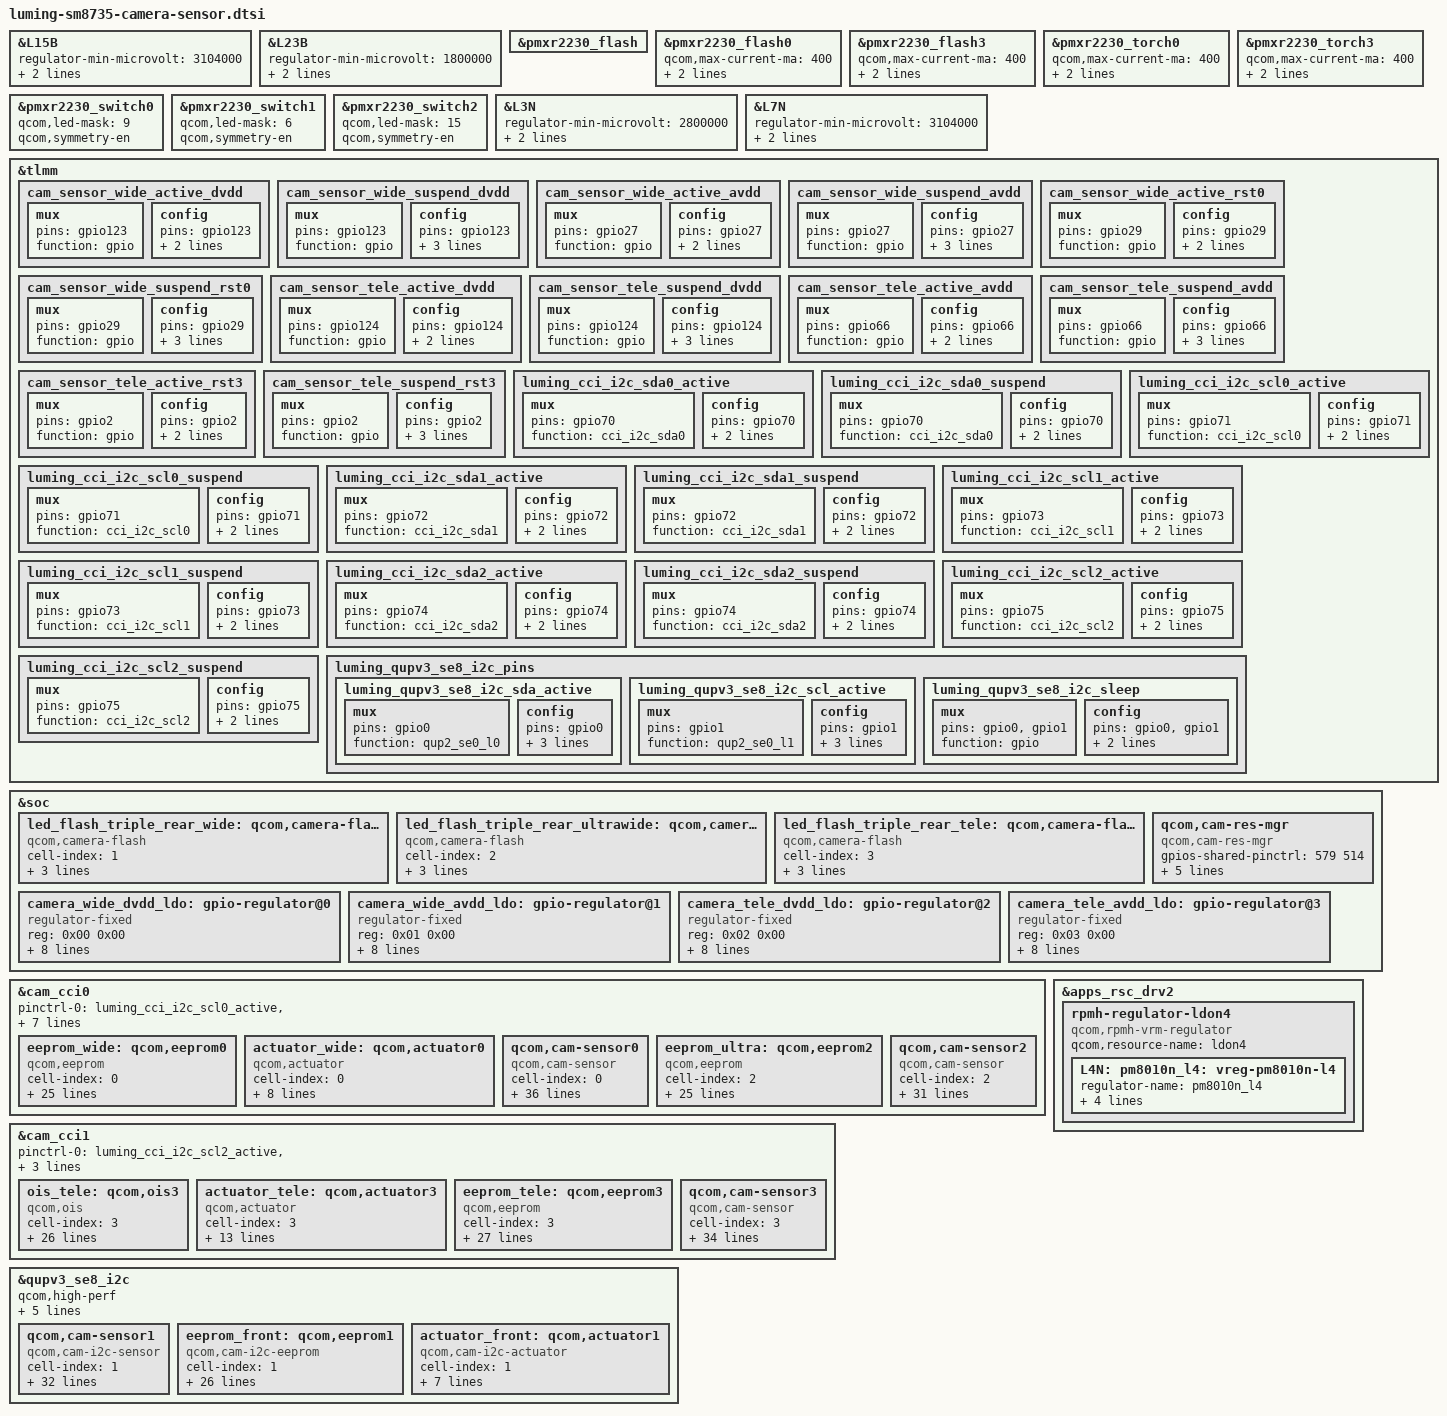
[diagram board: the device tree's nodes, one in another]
#include <dt-bindings/msm-camera.h>
&L15B {
	regulator-min-microvolt = <3104000>;
	regulator-max-microvolt = <3104000>;
	qcom,init-voltage = <3104000>;
};

&L23B {
	regulator-min-microvolt = <1800000>;
	regulator-max-microvolt = <1800000>;
	qcom,init-voltage = <1800000>;
};

&pmxr2230_flash {
	status = "ok";
};

&pmxr2230_flash0 {
	qcom,max-current-ma = <400>;
	qcom,duration-ms = <300>;
	xiaomi,max-duration-ms = <300>;
};

&pmxr2230_flash3 {
	qcom,max-current-ma = <400>;
	qcom,duration-ms = <300>;
	xiaomi,max-duration-ms = <300>;
};

&pmxr2230_torch0 {
	qcom,max-current-ma = <400>;
	xiaomi,currents-with-time = <400 150>;
	xiaomi,time-for-currents = <5000 0xFFFFFFFF>;
};

&pmxr2230_torch3 {
	qcom,max-current-ma = <400>;
	xiaomi,currents-with-time = <400 150>;
	xiaomi,time-for-currents = <5000 0xFFFFFFFF>;
};

&pmxr2230_switch0 {
	qcom,led-mask = <9>; /* Channels 1 & 4 */
	qcom,symmetry-en;
};

&pmxr2230_switch1 {
	qcom,led-mask = <6>; /* Channels 2 & 3 */
	qcom,symmetry-en;
};

&pmxr2230_switch2 {
	qcom,led-mask = <15>; /* All Channels */
	qcom,symmetry-en;
};


&L3N {
	regulator-min-microvolt = <2800000>;
	regulator-max-microvolt = <2800000>;
	qcom,init-voltage = <2800000>;
};

&L7N {
	regulator-min-microvolt = <3104000>;
	regulator-max-microvolt = <3104000>;
	qcom,init-voltage = <3104000>;
};

&tlmm {
	//WIDE DVDD
	cam_sensor_wide_active_dvdd: cam_sensor_wide_active_dvdd {
		mux {
			pins = "gpio123";
			function = "gpio";
		};
		config {
			pins = "gpio123";
			bias-disable; /* No PULL */
			drive-strength = <2>; /* 2 MA */
		};
	};
	cam_sensor_wide_suspend_dvdd: cam_sensor_wide_suspend_dvdd {
		mux {
			pins = "gpio123";
			function = "gpio";
		};
		config {
			pins = "gpio123";
			bias-pull-down; /* PULL DOWN */
			drive-strength = <2>; /* 2 MA */
			output-low;
		};
	};

	//WIDE AVDD
	cam_sensor_wide_active_avdd: cam_sensor_wide_active_avdd {
		mux {
			pins = "gpio27";
			function = "gpio";
		};
		config {
			pins = "gpio27";
			bias-disable; /* No PULL */
			drive-strength = <2>; /* 2 MA */
		};
	};
	cam_sensor_wide_suspend_avdd: cam_sensor_wide_suspend_avdd {
		mux {
			pins = "gpio27";
			function = "gpio";
		};
		config {
			pins = "gpio27";
			bias-pull-down; /* PULL DOWN */
			drive-strength = <2>; /* 2 MA */
			output-low;
		};
	};
	//WIDE RST
	cam_sensor_wide_active_rst0: cam_sensor_wide_active_rst0 {
		mux {
			pins = "gpio29";
			function = "gpio";
		};

		config {
			pins = "gpio29";
			bias-disable; /* No PULL */
			drive-strength = <2>; /* 2 MA */
		};
	};

	cam_sensor_wide_suspend_rst0: cam_sensor_wide_suspend_rst0 {
		mux {
			pins = "gpio29";
			function = "gpio";
		};

		config {
			pins = "gpio29";
			bias-pull-down; /* PULL DOWN */
			drive-strength = <2>; /* 2 MA */
			output-low;
		};
	};

	// Tele DVDD
	cam_sensor_tele_active_dvdd: cam_sensor_tele_active_dvdd {
		mux {
			pins = "gpio124";
			function = "gpio";
		};
		config {
			pins = "gpio124";
			bias-disable; /* No PULL */
			drive-strength = <2>; /* 2 MA */
		};
	};
	cam_sensor_tele_suspend_dvdd: cam_sensor_tele_suspend_dvdd {
		mux {
			pins = "gpio124";
			function = "gpio";
		};
		config {
			pins = "gpio124";
			bias-pull-down; /* PULL DOWN */
			drive-strength = <2>; /* 2 MA */
			output-low;
		};
	};

	//TELE AVDD
	cam_sensor_tele_active_avdd: cam_sensor_tele_active_avdd {
		mux {
			pins = "gpio66";
			function = "gpio";
		};
		config {
			pins = "gpio66";
			bias-disable; /* No PULL */
			drive-strength = <2>; /* 2 MA */
		};
	};
	cam_sensor_tele_suspend_avdd: cam_sensor_tele_suspend_avdd {
		mux {
			pins = "gpio66";
			function = "gpio";
		};
		config {
			pins = "gpio66";
			bias-pull-down; /* PULL DOWN */
			drive-strength = <2>; /* 2 MA */
			output-low;
		};
	};

	// Tele RST
	cam_sensor_tele_active_rst3: cam_sensor_tele_active_rst3 {
		mux {
			pins = "gpio2";
			function = "gpio";
		};

		config {
			pins = "gpio2";
			bias-disable; /* No PULL */
			drive-strength = <2>; /* 2 MA */
		};
	};

	cam_sensor_tele_suspend_rst3: cam_sensor_tele_suspend_rst3 {
		mux {
			pins = "gpio2";
			function = "gpio";
		};

		config {
			pins = "gpio2";
			bias-pull-down; /* PULL DOWN */
			drive-strength = <2>; /* 2 MA */
			output-low;
		};
	};

	// wide cci
	luming_cci_i2c_sda0_active: luming_cci_i2c_sda0_active {
		mux {
			pins = "gpio70";
			function = "cci_i2c_sda0";
		};

		config {
			pins = "gpio70";
			bias-disable; /* NO PULL */
			drive-strength = <2>; /* 2 MA */
		};
	};
	luming_cci_i2c_sda0_suspend: luming_cci_i2c_sda0_suspend {
		mux {
			pins = "gpio70";
			function = "cci_i2c_sda0";
		};

		config {
			pins = "gpio70";
			bias-disable; /* NO PULL */
			drive-strength = <2>; /* 2 MA */
		};
	};

	luming_cci_i2c_scl0_active: luming_cci_i2c_scl0_active {
		mux {
			pins = "gpio71";
			function = "cci_i2c_scl0";
		};

		config {
			pins = "gpio71";
			bias-disable; /* NO PULL */
			drive-strength = <2>; /* 2 MA */
		};
	};
	luming_cci_i2c_scl0_suspend: luming_cci_i2c_scl0_suspend {
		mux {
			pins = "gpio71";
			function = "cci_i2c_scl0";
		};
		config {
			pins = "gpio71";
			bias-disable; /* NO PULL */
			drive-strength = <2>; /* 2 MA */
		};
	};

	// ultra cci
	luming_cci_i2c_sda1_active: luming_cci_i2c_sda1_active {
		mux {
			pins = "gpio72";
			function = "cci_i2c_sda1";
		};

		config {
			pins = "gpio72";
			bias-disable; /* NO PULL */
			drive-strength = <2>; /* 2 MA */
		};
	};

	luming_cci_i2c_sda1_suspend: luming_cci_i2c_sda1_suspend {
		mux {
			pins = "gpio72";
			function = "cci_i2c_sda1";
		};
		config {
			pins = "gpio72";
			bias-disable; /* NO PULL */
			drive-strength = <2>; /* 2 MA */
		};
	};

	luming_cci_i2c_scl1_active: luming_cci_i2c_scl1_active {
		mux {
			pins = "gpio73";
			function = "cci_i2c_scl1";
		};

		config {
			pins = "gpio73";
			bias-disable; /* NO PULL */
			drive-strength = <2>; /* 2 MA */
		};
	};
	luming_cci_i2c_scl1_suspend: luming_cci_i2c_scl1_suspend {
		mux {
			pins = "gpio73";
			function = "cci_i2c_scl1";
		};
		config {
			pins = "gpio73";
			bias-disable; /* NO PULL */
			drive-strength = <2>; /* 2 MA */
		};
	};

	// tele cci
	luming_cci_i2c_sda2_active: luming_cci_i2c_sda2_active {
		mux {
			pins = "gpio74";
			function = "cci_i2c_sda2";
		};
		config {
			pins = "gpio74";
			bias-disable; /* NO PULL */
			drive-strength = <2>; /* 2 MA */
		};
	};
	luming_cci_i2c_sda2_suspend: luming_cci_i2c_sda2_suspend {
		mux {
			pins = "gpio74";
			function = "cci_i2c_sda2";
		};
		config {
			pins = "gpio74";
			bias-disable; /* NO PULL */
			drive-strength = <2>; /* 2 MA */
		};
	};


	luming_cci_i2c_scl2_active: luming_cci_i2c_scl2_active {
		mux {
			pins = "gpio75";
			function = "cci_i2c_scl2";
		};
		config {
			pins = "gpio75";
			bias-disable; /* NO PULL */
			drive-strength = <2>; /* 2 MA */
		};
	};
	luming_cci_i2c_scl2_suspend: luming_cci_i2c_scl2_suspend {
		mux {
			pins = "gpio75";
			function = "cci_i2c_scl2";
		};
		config {
			pins = "gpio75";
			bias-disable; /* NO PULL */
			drive-strength = <2>; /* 2 MA */
		};
	};
	luming_qupv3_se8_i2c_pins: luming_qupv3_se8_i2c_pins {
		luming_qupv3_se8_i2c_sda_active: luming_qupv3_se8_i2c_sda_active {
			mux {
				pins = "gpio0";
				function = "qup2_se0_l0";
			};

			config {
				pins = "gpio0";
				drive-strength = <2>;
				bias-disable;
				qcom,apps;
			};
		};

		luming_qupv3_se8_i2c_scl_active: luming_qupv3_se8_i2c_scl_active {
			mux {
				pins = "gpio1";
				function = "qup2_se0_l1";
			};

			config {
				pins = "gpio1";
				drive-strength = <2>;
				bias-disable;
				qcom,apps;
			};
		};
		luming_qupv3_se8_i2c_sleep: luming_qupv3_se8_i2c_sleep {
			mux {
				pins = "gpio0", "gpio1";
				function = "gpio";
			};

			config {
				pins = "gpio0", "gpio1";
				drive-strength = <2>;
				qcom,remote;
			};
		};
	};
};

&soc {
	led_flash_triple_rear_wide: qcom,camera-flash1 {
		cell-index = <1>;
		compatible = "qcom,camera-flash";
		flash-source = <&pmxr2230_flash0>;
		torch-source = <&pmxr2230_torch0>;
		switch-source = <&pmxr2230_switch0>;
		status = "ok";
	};

	led_flash_triple_rear_ultrawide: qcom,camera-flash2 {
		cell-index = <2>;
		compatible = "qcom,camera-flash";
		flash-source = <&pmxr2230_flash0>;
		torch-source = <&pmxr2230_torch0>;
		switch-source = <&pmxr2230_switch0>;
		status = "ok";
	};

	led_flash_triple_rear_tele: qcom,camera-flash3 {
		cell-index = <3>;
		compatible = "qcom,camera-flash";
		flash-source = <&pmxr2230_flash0>;
		torch-source = <&pmxr2230_torch0>;
		switch-source = <&pmxr2230_switch0>;
		status = "ok";
	};

	qcom,cam-res-mgr {
		compatible = "qcom,cam-res-mgr";
		gpios-shared-pinctrl = <579 514>;
		shared-pctrl-gpio-names = "cam_tele", "cam_tele";
		pinctrl-names = "cam_tele_active", "cam_tele_suspend";
		pinctrl-0 = <&cam_sensor_mclk3_active
					&cam_sensor_tele_active_rst3>;
		pinctrl-1 = <&cam_sensor_mclk3_suspend
					&cam_sensor_tele_suspend_rst3>;
		status = "ok";
	};

	camera_wide_dvdd_ldo: gpio-regulator@0 {
		compatible = "regulator-fixed";
		reg = <0x00 0x00>;
		regulator-name = "camera_wide_dvdd_ldo";
		regulator-min-microvolt = <1104000>;
		regulator-max-microvolt = <1104000>;
		regulator-enable-ramp-delay = <100>;
		enable-active-high;
		gpio = <&tlmm 123 0>;
		pinctrl-names = "wide_dvdd_active", "wide_dvdd_suspend";
		pinctrl-0 = <&cam_sensor_wide_active_dvdd
					 &cam_sensor_wide_suspend_dvdd>;
	};

	camera_wide_avdd_ldo: gpio-regulator@1 {
		compatible = "regulator-fixed";
		reg = <0x01 0x00>;
		regulator-name = "camera_wide_avdd_ldo";
		regulator-min-microvolt = <2800000>;
		regulator-max-microvolt = <2800000>;
		regulator-enable-ramp-delay = <100>;
		enable-active-high;
		gpio = <&tlmm 27 0>;
		pinctrl-names = "wide_avdd_active", "wide_avdd_suspend";
		pinctrl-0 = <&cam_sensor_wide_active_avdd
					 &cam_sensor_wide_suspend_avdd>;
	};

	camera_tele_dvdd_ldo: gpio-regulator@2 {
		compatible = "regulator-fixed";
		reg = <0x02 0x00>;
		regulator-name = "camera_tele_dvdd_ldo";
		regulator-min-microvolt = <1000000>;
		regulator-max-microvolt = <1000000>;
		regulator-enable-ramp-delay = <100>;
		enable-active-high;
		gpio = <&tlmm 124 0>;
		pinctrl-names = "tele_dvdd_active", "tele_dvdd_suspend";
		pinctrl-0 = <&cam_sensor_tele_active_dvdd
					 &cam_sensor_tele_suspend_dvdd>;
	};

	camera_tele_avdd_ldo: gpio-regulator@3 {
		compatible = "regulator-fixed";
		reg = <0x03 0x00>;
		regulator-name = "camera_tele_avdd_ldo";
		regulator-min-microvolt = <2200000>;
		regulator-max-microvolt = <2200000>;
		regulator-enable-ramp-delay = <100>;
		enable-active-high;
		gpio = <&tlmm 66 0>;
		pinctrl-names = "tele_avdd_active", "tele_avdd_suspend";
		pinctrl-0 = <&cam_sensor_tele_active_avdd
					 &cam_sensor_tele_suspend_avdd>;
	};
};

&cam_cci0 {
	pinctrl-0 = <&luming_cci_i2c_scl0_active &luming_cci_i2c_sda0_active>;
	pinctrl-1 = <&luming_cci_i2c_scl0_suspend &luming_cci_i2c_sda0_suspend>;
	pinctrl-2 = <&luming_cci_i2c_scl1_active &luming_cci_i2c_sda1_active>;
	pinctrl-3 = <&luming_cci_i2c_scl1_suspend &luming_cci_i2c_sda1_suspend>;
	// wide eeprom
	eeprom_wide: qcom,eeprom0 {
		cell-index = <0>;
		compatible = "qcom,eeprom";
		cam_vio-supply = <&L23B>;
		cam_vdig-supply = <&camera_wide_dvdd_ldo>;
		cam_clk-supply = <&cam_cc_titan_top_gdsc>;
		cam_vana-supply = <&camera_wide_avdd_ldo>;
		regulator-names = "cam_vio", "cam_vdig", "cam_clk", "cam_vana";
		rgltr-cntrl-support;
		rgltr-min-voltage = <1800000 1104000 0 2800000>;
		rgltr-max-voltage = <1800000 1104000 0 2800000>;
		rgltr-load-current = <4000 913000 0 119000>;
		gpio-no-mux = <0>;
		pinctrl-names = "cam_default", "cam_suspend";
		pinctrl-0 = <&cam_sensor_mclk0_active
				 &cam_sensor_wide_active_rst0>;
		pinctrl-1 = <&cam_sensor_mclk0_suspend
				 &cam_sensor_wide_suspend_rst0>;
		gpios = <&tlmm 64 0>,
			<&tlmm 29 0>;
		gpio-reset = <1>;
		gpio-req-tbl-num = <0 1>;
		gpio-req-tbl-flags = <1 0>;
		gpio-req-tbl-label = "CAMIF_MCLK0",
					"CAM_RESET0";
		cci-master = <CCI_MASTER_0>;
		clocks = <&cambistmclkcc CAM_BIST_MCLK_CC_MCLK0_CLK>;
		clock-names = "cam_clk";
		clock-cntl-level = "nominal";
		clock-rates = <19200000>;
		status = "ok";
	};

	// wide actuator
	actuator_wide: qcom,actuator0 {
		cell-index = <0>;
		compatible = "qcom,actuator";
		cci-master = <CCI_MASTER_0>;
		cam_vaf-supply = <&L15B>;
		cam_vio-supply = <&L23B>;
		regulator-names = "cam_vaf", "cam_vio";
		rgltr-cntrl-support;
		rgltr-min-voltage = <3104000 1800000>;
		rgltr-max-voltage = <3104000 1800000>;
		rgltr-load-current = <150000 150000>;
	};

	qcom,cam-sensor0 {
		cell-index = <0>;
		compatible = "qcom,cam-sensor";
		csiphy-sd-index = <0>;
		eeprom-src = <&eeprom_wide>;
		led-flash-src = <&led_flash_triple_rear_wide>;
		actuator-src = <&actuator_wide>;
		sensor-position-roll = <90>;
		sensor-position-pitch = <0>;
		sensor-position-yaw = <180>;
		cam_vio-supply = <&L23B>;
		cam_vdig-supply = <&camera_wide_dvdd_ldo>;
		cam_clk-supply = <&cam_cc_titan_top_gdsc>;
		//cam_vana-supply = <&L1B>;
		cam_vaf-supply = <&L15B>;
		//cam_bob2-supply = <&BOB2>;
		cam_vana-supply = <&camera_wide_avdd_ldo>;
		regulator-names = "cam_vio", "cam_vdig", "cam_clk", "cam_vana", "cam_vaf";
		rgltr-cntrl-support;
		rgltr-min-voltage = <1800000 1104000 0 2800000 3104000>;
		rgltr-max-voltage = <1800000 1104000 0 2800000 3104000>;
		rgltr-load-current = <4000 913000 0 119000 150000>;
		gpio-no-mux = <0>;
		pinctrl-names = "cam_default", "cam_suspend";
		pinctrl-0 = <&cam_sensor_mclk0_active
				 &cam_sensor_wide_active_rst0>;
		pinctrl-1 = <&cam_sensor_mclk0_suspend
				 &cam_sensor_wide_suspend_rst0>;
		gpios = <&tlmm 64 0>,
			<&tlmm 29 0>;
		gpio-reset = <1>;
		gpio-req-tbl-num = <0 1>;
		gpio-req-tbl-flags = <1 0>;
		gpio-req-tbl-label = "CAMIF_MCLK0",
					"CAM_RESET0";
		cci-master = <CCI_MASTER_0>;
		clocks = <&cambistmclkcc CAM_BIST_MCLK_CC_MCLK0_CLK>;
		clock-names = "cam_clk";
		clock-cntl-level = "nominal";
		clock-rates = <19200000>;
		status = "ok";
	};

	//ultra eeprom
	eeprom_ultra: qcom,eeprom2 {
		cell-index = <2>;
		compatible = "qcom,eeprom";
		cam_vana-supply = <&L3N>;
		cam_vio-supply = <&L23B>;
		cam_vdig-supply = <&L1N>;
		cam_clk-supply = <&cam_cc_titan_top_gdsc>;
		regulator-names = "cam_vana", "cam_vio", "cam_vdig", "cam_clk";
		rgltr-cntrl-support;
		rgltr-min-voltage = <2800000 1800000 1200000 0>;
		rgltr-max-voltage = <2800000 1800000 1200000 0>;
		rgltr-load-current = <57900 300 216200 0>;
		gpio-no-mux = <0>;
		pinctrl-names = "cam_default", "cam_suspend";
		pinctrl-0 = <&cam_sensor_mclk1_active
				 &cam_sensor_active_rst1>;
		pinctrl-1 = <&cam_sensor_mclk1_suspend
				 &cam_sensor_suspend_rst1>;
		gpios = <&tlmm 65 0>,
			<&tlmm 28 0>;
		gpio-reset = <1>;
		gpio-req-tbl-num = <0 1>;
		gpio-req-tbl-flags = <1 0>;
		gpio-req-tbl-label = "CAMIF_MCLK1",
					"CAM_RESET1";
		cci-master = <CCI_MASTER_1>;
		clocks = <&cambistmclkcc CAM_BIST_MCLK_CC_MCLK1_CLK>;
		clock-names = "cam_clk";
		clock-cntl-level = "nominal";
		clock-rates = <19200000>;
		status = "ok";
	};

	//ultra sensor
	qcom,cam-sensor2 {
		cell-index = <2>;
		compatible = "qcom,cam-sensor";
		csiphy-sd-index = <2>;
		eeprom-src = <&eeprom_ultra>;
		led-flash-src = <&led_flash_triple_rear_ultrawide>;
		sensor-position-roll = <90>;
		sensor-position-pitch = <0>;
		sensor-position-yaw = <180>;
		cam_vana-supply = <&L3N>;
		cam_vio-supply = <&L23B>;
		cam_vdig-supply = <&L1N>;
		cam_clk-supply = <&cam_cc_titan_top_gdsc>;
		regulator-names = "cam_vana", "cam_vio", "cam_vdig", "cam_clk";
		rgltr-cntrl-support;
		rgltr-min-voltage = <2800000 1800000 1200000 0>;
		rgltr-max-voltage = <2800000 1800000 1200000 0>;
		rgltr-load-current = <57900 300 216200 0>;
		gpio-no-mux = <0>;
		pinctrl-names = "cam_default", "cam_suspend";
		pinctrl-0 = <&cam_sensor_mclk1_active
				 &cam_sensor_active_rst1>;
		pinctrl-1 = <&cam_sensor_mclk1_suspend
				 &cam_sensor_suspend_rst1>;
		gpios = <&tlmm 65 0>,
			<&tlmm 28 0>;
		gpio-reset = <1>;
		gpio-req-tbl-num = <0 1>;
		gpio-req-tbl-flags = <1 0>;
		gpio-req-tbl-label = "CAMIF_MCLK1",
					"CAM_RESET1";
		cci-master = <CCI_MASTER_1>;
		clocks = <&cambistmclkcc CAM_BIST_MCLK_CC_MCLK1_CLK>;
		clock-names = "cam_clk";
		clock-cntl-level = "nominal";
		clock-rates = <19200000>;
		status = "ok";
	};
};

&cam_cci1 {
	pinctrl-0 = <&luming_cci_i2c_scl2_active &luming_cci_i2c_sda2_active>;
	pinctrl-1 = <&luming_cci_i2c_scl2_suspend &luming_cci_i2c_sda2_suspend>;
	// tele ois
	ois_tele: qcom,ois3 {
		cell-index = <3>;
		compatible = "qcom,ois";
		cam_vaf-supply = <&L7N>;
		cam_vdig-supply = <&camera_tele_dvdd_ldo>;
		cam_vana-supply = <&camera_tele_avdd_ldo>;
		cam_vio-supply = <&L23B>;
		cam_clk-supply = <&cam_cc_titan_top_gdsc>;
		regulator-names = "cam_vaf", "cam_vio", "cam_vdig", "cam_clk", "cam_vana";
		rgltr-cntrl-support;
		rgltr-min-voltage = <3104000 1800000 1000000 0 2200000>;
		rgltr-max-voltage = <3104000 1800000 1000000 0 2200000>;
		rgltr-load-current = <150000 50000 590000 0  85000>;
		gpio-no-mux = <0>;
		use-shared-clk;
		gpios = <&tlmm 67 0>,
			<&tlmm 2 0>;
		gpio-reset = <1>;
		gpio-req-tbl-num = <0 1>;
		gpio-req-tbl-flags = <1 0>;
		gpio-req-tbl-label = "CAMIF_MCLK3",
					"CAM_RESET3";
		cci-master = <CCI_MASTER_0>;
		clocks = <&cambistmclkcc CAM_BIST_MCLK_CC_MCLK3_CLK>;
		clock-names = "cam_clk";
		clock-cntl-level = "nominal";
		clock-rates = <19200000>;
		status = "ok";
	};

	// tele actuator
	actuator_tele: qcom,actuator3 {
		cell-index = <3>;
		compatible = "qcom,actuator";
		cci-master = <CCI_MASTER_0>;
		cam_vaf-supply = <&L7N>;
		cam_vio-supply = <&L23B>;
		cam_vdig-supply = <&camera_tele_dvdd_ldo>;
		cam_vana-supply = <&camera_tele_avdd_ldo>;
		regulator-names = "cam_vaf", "cam_vio", "cam_vdig", "cam_vana";
		rgltr-cntrl-support;
		rgltr-min-voltage = <3104000 1800000 1000000 2200000>;
		rgltr-max-voltage = <3104000 1800000 1000000 2200000>;
		rgltr-load-current = <150000 50000 590000  85000>;
	};

	// tele eeprom
    eeprom_tele: qcom,eeprom3 {
		cell-index = <3>;
		compatible = "qcom,eeprom";
		csiphy-sd-index = <3>;
		cam_vaf-supply = <&L7N>;
		cam_vio-supply = <&L23B>;
		cam_vdig-supply = <&camera_tele_dvdd_ldo>;
		cam_clk-supply = <&cam_cc_titan_top_gdsc>;
		// cam_bob2-supply = <&BOB2>;
		cam_vana-supply = <&camera_tele_avdd_ldo>;
		regulator-names = "cam_vaf", "cam_vio", "cam_vdig", "cam_clk", "cam_vana";
		rgltr-cntrl-support;
		rgltr-min-voltage = <3104000 1800000 1000000 0 2200000>;
		rgltr-max-voltage = <3104000 1800000 1000000 0 2200000>;
		rgltr-load-current = <150000 50000 590000 0  85000>;
		gpio-no-mux = <0>;
		use-shared-clk;
		//pinctrl-names = "cam_default", "cam_suspend";
		//pinctrl-0 = <&cam_sensor_mclk3_active
		//		 &cam_sensor_tele_active_rst3>;
		//pinctrl-1 = <&cam_sensor_mclk3_suspend
		//		 &cam_sensor_tele_suspend_rst3>;
		gpios = <&tlmm 67 0>,
			<&tlmm 2 0>;
		gpio-reset = <1>;
		gpio-req-tbl-num = <0 1>;
		gpio-req-tbl-flags = <1 0>;
		gpio-req-tbl-label = "CAMIF_MCLK3",
					"CAM_RESET3";
		cci-master = <CCI_MASTER_0>;
		clocks = <&cambistmclkcc CAM_BIST_MCLK_CC_MCLK3_CLK>;
		clock-names = "cam_clk";
		clock-cntl-level = "nominal";
		clock-rates = <19200000>;
		status = "ok";
	};

	// tele Sensor
	qcom,cam-sensor3 {
		cell-index = <3>;
		compatible = "qcom,cam-sensor";
		csiphy-sd-index = <3>;
		led-flash-src = <&led_flash_triple_rear_tele>;
		eeprom-src = <&eeprom_tele>;
		actuator-src = <&actuator_tele>;
		ois-src = <&ois_tele>;
		sensor-position-roll = <90>;
		sensor-position-pitch = <0>;
		sensor-position-yaw = <180>;
		cam_vaf-supply = <&L7N>;
		cam_vio-supply = <&L23B>;
		cam_vdig-supply = <&camera_tele_dvdd_ldo>;
		cam_clk-supply = <&cam_cc_titan_top_gdsc>;
		// cam_bob2-supply = <&BOB2>;
		cam_vana-supply = <&camera_tele_avdd_ldo>;
		regulator-names = "cam_vaf", "cam_vio", "cam_vdig", "cam_clk", "cam_vana";
		rgltr-cntrl-support;
		rgltr-min-voltage = <3104000 1800000 1000000 0 2200000>;
		rgltr-max-voltage = <3104000 1800000 1000000 0 2200000>;
		rgltr-load-current = <150000 50000 590000 0  85000>;
		gpio-no-mux = <0>;
		use-shared-clk;
		//pinctrl-names = "cam_default", "cam_suspend";
		//pinctrl-0 = <&cam_sensor_mclk3_active
		//		 &cam_sensor_tele_active_rst3>;
		//pinctrl-1 = <&cam_sensor_mclk3_suspend
		//		 &cam_sensor_tele_suspend_rst3>;
		gpios = <&tlmm 67 0>,
			<&tlmm 2 0>;
		gpio-reset = <1>;
		gpio-req-tbl-num = <0 1>;
		gpio-req-tbl-flags = <1 0>;
		gpio-req-tbl-label = "CAMIF_MCLK3",
					"CAM_RESET3";
		cci-master = <CCI_MASTER_0>;
		clocks = <&cambistmclkcc CAM_BIST_MCLK_CC_MCLK3_CLK>;
		clock-names = "cam_clk";
		clock-cntl-level = "nominal";
		clock-rates = <19200000>;
		status = "ok";
	};

};

&apps_rsc_drv2 {
	rpmh-regulator-ldon4 {
		compatible = "qcom,rpmh-vrm-regulator";
		qcom,resource-name = "ldon4";
		status = "ok";

		L4N: pm8010n_l4: vreg-pm8010n-l4 {
			regulator-name = "pm8010n_l4";
			qcom,set = <RPMH_REGULATOR_SET_ALL>;
			regulator-min-microvolt = <1792000>;
			regulator-max-microvolt = <3312000>;
			qcom,init-voltage = <1800000>;
		status = "ok";
		};
	};
};

&qupv3_se8_i2c {
	status = "ok";
	qcom,high-perf;
	qcom,clk-freq-out = <1000000>;
	qcom,pm-ctrl-client;
	pinctrl-0 = <&luming_qupv3_se8_i2c_sda_active>, <&luming_qupv3_se8_i2c_scl_active>;
	pinctrl-1 = <&luming_qupv3_se8_i2c_sleep>;

	// Front Sensor
	qcom,cam-sensor1 {
		cell-index = <1>;
		reg = <0x10>;
		compatible = "qcom,cam-i2c-sensor";
		csiphy-sd-index = <4>;
		eeprom-src = <&eeprom_front>;
		actuator-src = <&actuator_front>;
		sensor-position-roll = <270>;
		sensor-position-pitch = <0>;
		sensor-position-yaw = <0>;
		cam_vana-supply = <&L4N>;
		cam_vio-supply = <&L5N>;
		cam_vdig-supply = <&L2N>;
		// cam_bob1-supply = <&BOB1>;
		cam_clk-supply = <&cam_cc_titan_top_gdsc>;
		regulator-names = "cam_vana", "cam_vio",
			"cam_vdig", "cam_clk";
		rgltr-cntrl-support;
		aon-camera-id = <AON_CAM1>;
		rgltr-min-voltage = <2200000 1800000 1056000 0>;
		rgltr-max-voltage = <2200000 1800000 1056000 0>;
		rgltr-load-current = <150000 150000 150000 0>;
		gpio-no-mux = <0>;
		pinctrl-names = "cam_default", "cam_suspend";
		pinctrl-0 = <&cam_sensor_mclk4_active
			&cam_sensor_active_rst3>;
		pinctrl-1 = <&cam_sensor_mclk4_suspend
			&cam_sensor_suspend_rst3>;
		gpios = <&tlmm 68 0>, <&tlmm 3 0>;
		gpio-reset = <1>;
		gpio-req-tbl-num = <0 1>;
		gpio-req-tbl-flags = <1 0>;
		gpio-req-tbl-label = "CAMIF_MCLK4", "CAM_RESET3";
		clocks = <&cambistmclkcc CAM_BIST_MCLK_CC_MCLK4_CLK>;
		clock-names = "cam_clk";
		clock-cntl-level = "nominal";
		clock-rates = <19200000>;
		status = "ok";
	};

	// Front eeprom
	eeprom_front: qcom,eeprom1 {
		cell-index = <1>;
		reg = <0x51>;
		compatible = "qcom,cam-i2c-eeprom";
		cam_vana-supply = <&L4N>;
		cam_vio-supply = <&L5N>;
		cam_vdig-supply = <&L2N>;
		// cam_bob1-supply = <&BOB1>;
		cam_clk-supply = <&cam_cc_titan_top_gdsc>;
		regulator-names = "cam_vana", "cam_vio",
			"cam_vdig", "cam_clk";
		rgltr-cntrl-support;
		aon-camera-id = <AON_CAM1>;
		rgltr-min-voltage = <2200000 1800000 1056000 0>;
		rgltr-max-voltage = <2200000 1800000 1056000 0>;
		rgltr-load-current = <150000 150000 150000 0>;
		gpio-no-mux = <0>;
		pinctrl-names = "cam_default", "cam_suspend";
		pinctrl-0 = <&cam_sensor_mclk4_active
			&cam_sensor_active_rst3>;
		pinctrl-1 = <&cam_sensor_mclk4_suspend
			&cam_sensor_suspend_rst3>;
		gpios = <&tlmm 68 0>, <&tlmm 3 0>;
		gpio-reset = <1>;
		gpio-req-tbl-num = <0 1>;
		gpio-req-tbl-flags = <1 0>;
		gpio-req-tbl-label = "CAMIF_MCLK4", "CAM_RESET3";
		clocks = <&cambistmclkcc CAM_BIST_MCLK_CC_MCLK4_CLK>;
		clock-names = "cam_clk";
		clock-cntl-level = "nominal";
		clock-rates = <19200000>;
		status = "ok";
	};

	// Front actuator
	actuator_front: qcom,actuator1 {
		cell-index = <1>;
		reg = <0x0C>;
		compatible = "qcom,cam-i2c-actuator";
		cam_vaf-supply = <&L6N>;
		regulator-names = "cam_vaf";
		rgltr-cntrl-support;
		rgltr-min-voltage = <2800000>;
		rgltr-max-voltage = <2800000>;
		rgltr-load-current = <103000>;
		status = "ok";
	};
};
